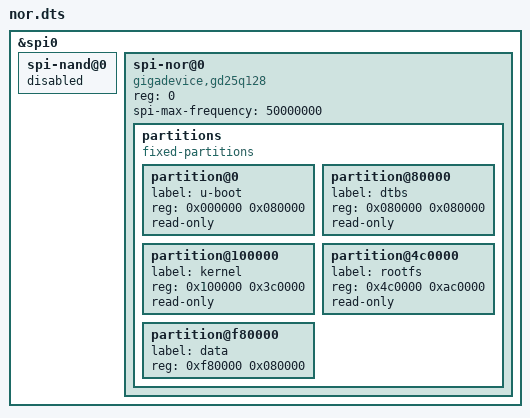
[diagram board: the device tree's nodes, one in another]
// SPDX-License-Identifier: (GPL-2.0+ OR X11)
/dts-v1/;
/plugin/;

&spi0 {
	#address-cells = <1>;
	#size-cells = <1>;

	spi-nand@0 {
		status = "disabled";
	};

	spi-nor@0 {
		compatible = "gigadevice,gd25q128", "jedec,spi-nor";
		reg = <0>;
		spi-max-frequency = <50000000>;
		#address-cells = <1>;
		#size-cells = <1>;

		partitions {
			compatible = "fixed-partitions";
			#address-cells = <1>;
			#size-cells = <1>;

			partition@0 {
				label = "u-boot";
				reg = <0x000000 0x080000>;
				read-only;
			};

			partition@80000 {
				label = "dtbs";
				reg = <0x080000 0x080000>;
				read-only;
			};

			partition@100000 {
				label = "kernel";
				reg = <0x100000 0x3c0000>;
				read-only;
			};

			partition@4c0000 {
				label = "rootfs";
				reg = <0x4c0000 0xac0000>;
				read-only;
			};

			partition@f80000 {
				label = "data";
				reg = <0xf80000 0x080000>;
			};
		};
	};
};
